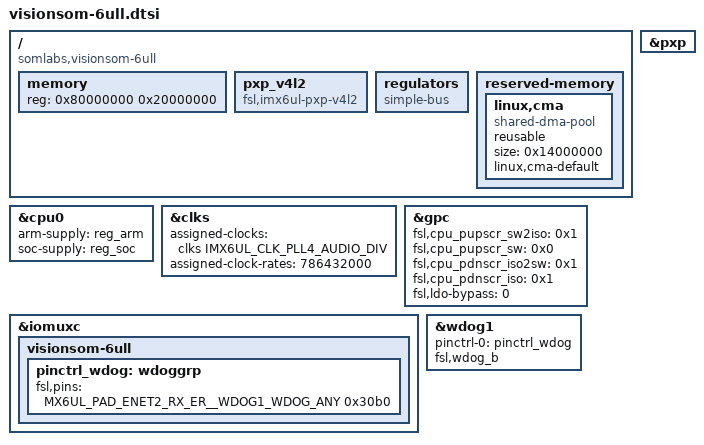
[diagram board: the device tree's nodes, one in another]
/*
 * Copyright (C) 2020 SoMLabs
 *
 * This program is free software; you can redistribute it and/or modify
 * it under the terms of the GNU General Public License version 2 as
 * published by the Free Software Foundation.
 */

/dts-v1/;

#include <dt-bindings/input/input.h>
#include "imx6ull.dtsi"

/ {
        compatible = "somlabs,visionsom-6ull", "fsl,imx6ull";

        memory {
                reg = <0x80000000 0x20000000>;
        };

        pxp_v4l2 {
                compatible = "fsl,imx6ul-pxp-v4l2", "fsl,imx6sx-pxp-v4l2", "fsl,imx6sl-pxp-v4l2";
                status = "okay";
        };

       regulators {
                compatible = "simple-bus";
                #address-cells = <1>;
                #size-cells = <0>;
        };

        reserved-memory {
                #address-cells = <1>;
                #size-cells = <1>;
                ranges;

                linux,cma {
                        compatible = "shared-dma-pool";
                        reusable;
                        size = <0x14000000>;
                        linux,cma-default;
                };
        };
};

&cpu0 {
        arm-supply = <&reg_arm>;
        soc-supply = <&reg_soc>;
};

&clks {
        assigned-clocks = <&clks IMX6UL_CLK_PLL4_AUDIO_DIV>;
        assigned-clock-rates = <786432000>;
};

&gpc {
        fsl,cpu_pupscr_sw2iso = <0x1>;
        fsl,cpu_pupscr_sw = <0x0>;
        fsl,cpu_pdnscr_iso2sw = <0x1>;
        fsl,cpu_pdnscr_iso = <0x1>;
        fsl,ldo-bypass = <0>; /* DCDC, ldo-enable */
};

&iomuxc {
        pinctrl-names = "default";
        visionsom-6ull {
                pinctrl_wdog: wdoggrp {
                        fsl,pins = <MX6UL_PAD_ENET2_RX_ER__WDOG1_WDOG_ANY 0x30b0>;
                };
        };

};

&pxp {
        status = "okay";
};

&wdog1 {
        pinctrl-names = "default";
        pinctrl-0 = <&pinctrl_wdog>;
        fsl,wdog_b;
};

